# LPC43xx register map
File version: 5
Registers are 32-bit, read-write, reset 0x0 unless marked. A register's access mark holds for its fields unless they carry their own. Offsets are from the block's base; [hi:lo] are bit positions.

## ETHERNET (part 2 of 2) — Product name title=UM10430 Chapter title=LPC18xx Ethernet Modification date=12/9/2011 Major revision=1.1 Minor revision=not available
Base 0x40010000
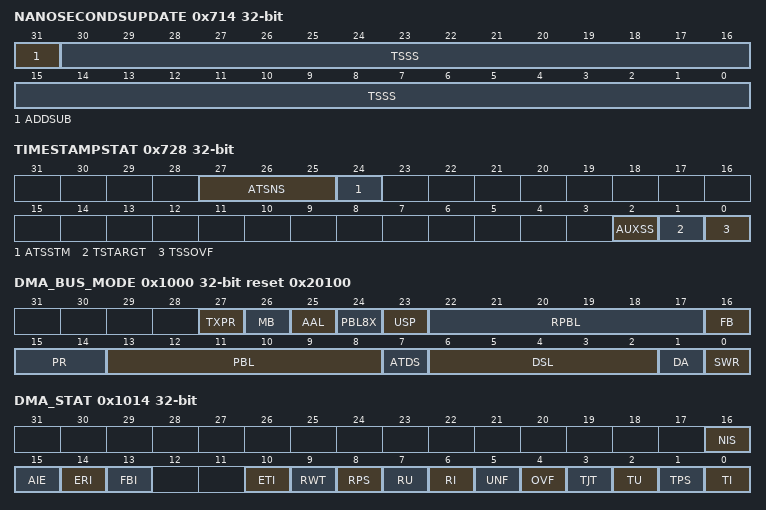
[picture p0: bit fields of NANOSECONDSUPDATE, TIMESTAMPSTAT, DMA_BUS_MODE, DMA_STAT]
0x714 NANOSECONDSUPDATE — System time nanoseconds update register
  [31] ADDSUB — Add or subtract time When this bit is set, the time value is subtracted with the contents of the update register. When this bit is reset, the time value is added with the contents of the update register.
  [30:0] TSSS — Time stamp sub seconds The value in this field has the sub second representation of time, with an accuracy of 0.46 nano-second. (When TSCTRLSSR is set in the time stamp control register, each bit represents 1 ns and the programmed value should not exceed 0x3B9A_C9FF.)
0x718 ADDEND — Time stamp addend register
  [31:0] TSAR — Time stamp addend This register indicates the 32-bit time value to be added to the Accumulator register to achieve time synchronization.
0x71C TARGETSECONDS — Target time seconds register
  [31:0] TSTR — Target time seconds register This register stores the time in seconds. When the time stamp value matches or exceeds both Target Time Stamp registers, the MAC, if enabled, generates an interrupt.
0x720 TARGETNANOSECONDS — Target time nanoseconds register
  [30:0] TSTR — Target time stamp low This register stores the time in (signed) nanoseconds. When the value of the Time Stamp matches the Target time stamp registers (both), the MAC will generate an interrupt if enabled. (This value should not exceed 0x3B9A_C9FF when TSCTRLSSR is set in the time stamp control register.)
0x724 HIGHWORD — System time higher word seconds register
  [15:0] TSHWR — Time stamp higher word Contains the most significant 16-bits of the time stamp seconds value. The register is directly written to initialize the value. This register is incremented when there is an overflow from the 32-bits of the System Time - Seconds register.
0x728 TIMESTAMPSTAT ro — Time stamp status register
  [27:25] ATSNS — Auxiliary Time Stamp Number of Snapshots These bits indicate the number of Snapshots available in the FIFO. A value of 4 (100) indicates that the Auxiliary Snapshot FIFO is full. These bits are cleared (to 000) when the Auxiliary snapshot FIFO clear bit is set.
  [24] ATSSTM — Auxiliary Time Stamp Snapshot Trigger Missed This bit is set when the Auxiliary time stamp snapshot FIFO is full and external trigger was set. This indicates that the latest snapshot was not stored in the FIFO.
  [2] AUXSS — Auxiliary Time Stamp Trigger Snapshot This bit is set high when the auxiliary snapshot is written to the FIFO.
  [1] TSTARGT — Time stamp target reached When set, indicates the value of system time is greater or equal to the value specified in the Target Time High and Low registers
  [0] TSSOVF — Time stamp seconds overflow When set, indicates that the seconds value of the time stamp (when supporting version 2 format) has overflowed beyond 0xFFFF_FFFF.
0x72C PPSCTRL — PPS control register
  [3:0] PPSCTRL — Control the duration between 2-pulses of PPS signal output This controls the duration between 2 pulses of the PPS output signal. By default the control is set to 1 second between pulses. The duration of the pulses for valid settings is mentioned below. 0000 = 1.0 sec (Binary and Digital Rollover) 0001 = 0.5 sec (Binary Rollover), 0.536 sec (Digital Rollover) 0010 = 0.25 sec (Binary Rollover), 0.26 sec (Digital Rollover) 0011 = 0.125 sec (Binary Rollover), 0.13 sec (Digital Rollover) ... 1111 = 15.28 msec (Binary Rollover), 32.77 microsec (Digital Rollover)
0x730 AUXNANOSECONDS ro — Auxiliary time stamp nanoseconds register
  [31:0] AUXNS — Lower 32 bits (nano-seconds field) of the auxiliary time stamp.
0x734 AUXSECONDS ro — Auxiliary time stamp seconds register
  [31:0] AUXS — Lower 32 bits of the Seconds field of the auxiliary time stamp .
0x1000 DMA_BUS_MODE reset 0x20100 — Bus Mode Register
  [27] TXPR — When set, this bit indicates that the transmit DMA has higher priority than the receive DMA during arbitration for the system-side bus.
  [26] MB — Mixed burst When this bit is set high and FB bit is low, the AHB master interface will start all bursts of length more than 16 with INCR (undefined burst) whereas it will revert to fixed burst transfers (INCRx and SINGLE) for burst-length of 16 and below.
  [25] AAL — Address-aligned beats When this bit is set high and the FB bit equals 1, the AHB interface generates all bursts aligned to the start address LS bits. If the FB bit equals 0, the first burst (accessing the data buffer's start address) is not aligned, but subsequent bursts are aligned to the address.
  [24] PBL8X — 8 x PBL mode When set high, this bit multiplies the PBL value programmed (bits [22:17] and bits [13:8]) eight times. Thus the DMA will transfer data in to a maximum of 8, 16, 32, 64, 128, and 256 beats depending on the PBL value. This bit function is not backward compatible. Before version 3.50a, this bit was 4xPBL.
  [23] USP — Use separate PBL When set high, it configures the RxDMA to use the value configured in bits [22:17] as PBL while the PBL value in bits [13:8] is applicable to TxDMA operations only. When reset to low, the PBL value in bits [13:8] is applicable for both DMA engines.
  [22:17] RPBL — RxDMA PBL These bits indicate the maximum number of beats to be transferred in one RxDMA transaction. This will be the maximum value that is used in a single block Read/Write. The RxDMA will always attempt to burst as specified in RPBL each time it starts a Burst transfer on the host bus. RPBL can be programmed with permissible values of 1, 2, 4, 8, 16, and 32. Any other value will result in undefined behavior. These bits are valid and applicable only when USP is set high.
  [16] FB — Fixed burst This bit controls whether the AHB Master interface performs fixed burst transfers or not. When set, the AHB will use only SINGLE, INCR4, INCR8 or INCR16 during start of normal burst transfers. When reset, the AHB will use SINGLE and INCR burst transfer operations.
  [15:14] PR — Rx-to-Tx priority ratio RxDMA requests given priority over TxDMA requests in the following ratio. This is valid only when the DA bit is reset. 00 = 1-to-1 01 = 2-to-1 10 = 3-to-1 11 = 4-to-1
  [13:8] PBL — Programmable burst length These bits indicate the maximum number of beats to be transferred in one DMA transaction. This will be the maximum value that is used in a single block Read/Write. The DMA will always attempt to burst as specified in PBL each time it starts a Burst transfer on the host bus. PBL can be programmed with permissible values of 1, 2, 4, 8, 16, and 32. Any other value will result in undefined behavior. When USP is set high, this PBL value is applicable for TxDMA transactions only. The PBL values have the following limitations. The maximum number of beats (PBL) possible is limited by the size of the Tx FIFO and Rx FIFO in the MTL layer and the data bus width on the DMA. The FIFO has a constraint that the maximum beat supported is half the depth of the FIFO, except when specified (as given below). For different data bus widths and FIFO sizes, the valid PBL range (including x8 mode) is provided in the following table. If the PBL is common for both transmit and receive DMA, the minimum Rx FIFO and Tx FIFO depths must be considered. Do not program out-of-range PBL values, because the system may not behave properly.
  [7] ATDS — Alternate descriptor size When set, the alternate descriptor (see Section 24.10.3) size is increased to 32 bytes (8 DWORDS). This is required when the Advanced Time-Stamp feature or Full IPC Offload Engine is enabled in the receiver. When reset, the descriptor size reverts back to 4 DWORDs (16 bytes).
  [6:2] DSL — Descriptor skip length This bit specifies the number of Word/Dword/Lword (depending on 32/64/128-bit bus) to skip between two unchained descriptors. The address skipping starts from the end of current descriptor to the start of next descriptor. When DSL value equals zero, then the descriptor table is taken as contiguous by the DMA, in Ring mode.
  [1] DA — DMA arbitration scheme 0 = Round-robin with Rx:Tx priority given in bits [15:14] 1 = Rx has priority over Tx
  [0] SWR — Software reset This register field can be read by the application (Read), can be set to 1 by the application with a register write of 1 (Write Set), and is cleared to 0 by the Ethernet core (Self Clear). The application cannot clear this type of field, and a register write of 0 to this bit has no effect on this field. When this bit is set, the MAC DMA Controller resets all MAC Subsystem internal registers and logic. It is cleared automatically after the reset operation has completed in all of the core clock domains. Read a 0 value in this bit before re-programming any register of the core. The reset operation is completed only when all the resets in all the active clock domains are de-asserted. Hence it is essential that all the PHY inputs clocks (applicable for the selected PHY interface) are present for software reset completion.
0x1004 DMA_TRANS_POLL_DEMAND — Transmit poll demand register
  [31:0] TPD — Transmit poll demand This register field can be read by the application, and when a write operation is performed with any data value, an event is triggered. When these bits are written with any value, the DMA reads the current descriptor pointed to by the Current Host Transmit Descriptor register (Section 24.6.40). If that descriptor is not available (owned by Host), transmission returns to the Suspend state and bit 2 in the DMA_STAT Register is asserted. If the descriptor is available, transmission resumes.
0x1008 DMA_REC_POLL_DEMAND — Receive poll demand register
  [31:0] RPD — Receive poll demand This register field can be read by the application, and when a write operation is performed with any data value, an event is triggered. When these bits are written with any value, the DMA reads the current descriptor pointed to by the Current Host Receive Descriptor register (Section 24.6.41). If that descriptor is not available (owned by Host), reception returns to the Suspended state and bit 7 in the DMA_STAT Register is not asserted. If the descriptor is available, the Receive DMA returns to active state.
0x100C DMA_REC_DES_ADDR — Receive descriptor list address register
  [31:0] SRL — Start of receive list This field contains the base address of the First Descriptor in the Receive Descriptor list. The LSB bits [1/2/3:0] for 32/64/128-bit bus width) will be ignored and taken as all-zero by the DMA internally. Hence these LSB bits are Read Only.
0x1010 DMA_TRANS_DES_ADDR — Transmit descriptor list address register
  [31:0] SRL — Start of transmit list This field contains the base address of the First Descriptor in the Transmit Descriptor list. The LSB bits [1/2/3:0] for 32/64/128-bit bus width) will be ignored and taken as all-zero by the DMA internally. Hence these LSB bits are Read Only.
0x1014 DMA_STAT — Status register
  [16] NIS — Normal interrupt summary Normal Interrupt Summary bit value is the logical OR of the following when the corresponding interrupt bits are enabled in the DMA_INT_EN register: DMA_STAT register, bit 0: Transmit interrupt DMA_STAT register, bit 2: Transmit buffer unavailable DMA_STAT register, bit 6: Receive interrupt DMA_STAT register, bit 14: Early receive interrupt Only unmasked bits affect the Normal Interrupt Summary bit. This is a sticky bit and must be cleared (by writing a 1 to this bit) each time a corresponding bit that causes NIS to be set is cleared.
  [15] AIE — Abnormal interrupt summary Abnormal Interrupt Summary bit value is the logical OR of the following when the corresponding interrupt bits are enabled in the DMA_INT_EN register: DMA_STAT register, bit 1: Transmit process stopped DMA_STAT register, bit 3: Transmit jabber timeout DMA_STAT register, bit 4: Receive overflow DMA_STAT register, bit 5: Transmit underflow DMA_STAT register, bit 7: Receiver buffer unavailable DMA_STAT register, bit 8: Receive process stopped DMA_STAT register, bit 9: Receive watchdog timeout DMA_STAT register, bit 10: Early transmit interrupt DMA_STAT register, bit 13: Fatal bus error Only unmasked bits affect the Abnormal Interrupt Summary bit. This is a sticky bit and must be cleared each time a corresponding bit that causes AIS to be set is cleared.
  [14] ERI — Early receive interrupt This bit indicates that the DMA had filled the first data buffer of the packet. Receive Interrupt bit 6 in this register automatically clears this bit.
  [13] FBI — Fatal bus error interrupt This bit indicates that a bus error occurred, as detailed in bits [25:23]. When this bit is set, the corresponding DMA engine disables all its bus accesses.
  [10] ETI — Early transmit interrupt This bit indicates that the frame to be transmitted was fully transferred to the MTL Transmit FIFO.
  [9] RWT — Receive watchdog timeout This bit is asserted when a frame with a length greater than 2,048 bytes is received (10,240 when Jumbo Frame mode is enabled).
  [8] RPS — Received process stopped This bit is asserted when the Receive Process enters the Stopped state.
  [7] RU — Receive buffer unavailable This bit indicates that the Next Descriptor in the Receive List is owned by the host and cannot be acquired by the DMA. Receive Process is suspended. To resume processing Receive descriptors, the host should change the ownership of the descriptor and issue a Receive Poll Demand command. If no Receive Poll Demand is issued, Receive Process resumes when the next recognized incoming frame is received. This bit is set only when the previous Receive Descriptor was owned by the DMA.
  [6] RI — Receive interrupt This bit indicates the completion of frame reception. Specific frame status information has been posted in the descriptor. Reception remains in the Running state.
  [5] UNF — Transmit underflow This bit indicates that the Transmit Buffer had an Underflow during frame transmission. Transmission is suspended and an Underflow Error TDES0[1] is set.
  [4] OVF — Receive overflow This bit indicates that the Receive Buffer had an Overflow during frame reception. If the partial frame is transferred to application, the overflow status is set in RDES0[11].
  [3] TJT — Transmit jabber timeout This bit indicates that the Transmit Jabber Timer expired, meaning that the transmitter had been excessively active. The transmission process is aborted and placed in the Stopped state. This causes the Transmit Jabber Timeout TDES0[14] flag to assert.
  [2] TU — Transmit buffer unavailable This bit indicates that the Next Descriptor in the Transmit List is owned by the host and cannot be acquired by the DMA. Transmission is suspended. Bits[22:20] explain the Transmit Process state transitions. To resume processing transmit descriptors, the host should change the ownership of the bit of the descriptor and then issue a Transmit Poll Demand command.
  [1] TPS — Transmit process stopped This bit is set when the transmission is stopped.
  [0] TI — Transmit interrupt This bit indicates that frame transmission is finished and TDES1[31] is set in the First Descriptor.
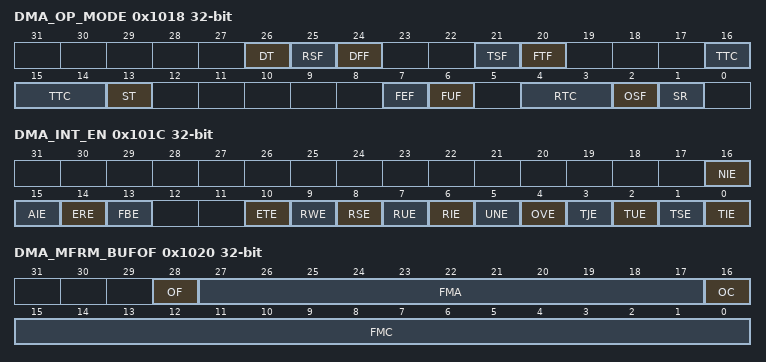
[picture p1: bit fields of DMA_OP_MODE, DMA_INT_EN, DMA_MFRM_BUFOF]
0x1018 DMA_OP_MODE — Operation mode register
  [26] DT — Disable Dropping of TCP/IP Checksum Error Frames When this bit is set, the core does not drop frames that only have errors detected by the Receive Checksum Offload engine. Such frames do not have any errors (including FCS error) in the Ethernet frame received by the MAC but have errors in the encapsulated payload only. When this bit is reset, all error frames are dropped if the FEF bit is reset.
  [25] RSF — Receive store and forward When this bit is set, the MTL only reads a frame from the Rx FIFO after the complete frame has been written to it, ignoring RTC bits. When this bit is reset, the Rx FIFO operates in Cut-Through mode, subject to the threshold specified by the RTC bits.
  [24] DFF — Disable flushing of received frames When this bit is set, the RxDMA does not flush any frames due to the unavailability of receive descriptors/buffers as it does normally when this bit is reset. (See).
  [21] TSF — Transmit store and forward When this bit is set, transmission starts when a full frame resides in the MTL Transmit FIFO. When this bit is set, the TTC values specified in this register (bits [16:14]) are ignored. This bit should be changed only when transmission is stopped.
  [20] FTF — Flush transmit FIFO This register field can be read by the application (Read), can be set to 1 by the application with a register write of 1 (Write Set), and is cleared to 0 by the Ethernet core (Self Clear). The application cannot clear this type of field, and a register write of 0 to this bit has no effect on this field. When this bit is set, the transmit FIFO controller logic is reset to its default values and thus all data in the Tx FIFO is lost/flushed. This bit is cleared internally when the flushing operation is completed fully. The Operation Mode register should not be written to until this bit is cleared. The data which is already accepted by the MAC transmitter will not be flushed. It will be scheduled for transmission and will result in underflow and runt frame transmission. The flush operation completes only after emptying the TxFIFO of its contents and all the pending Transmit Status of the transmitted frames are accepted by the host. In order to complete this flush operation, the PHY transmit clock is required to be active.
  [16:14] TTC — Transmit threshold control These three bits control the threshold level of the MTL Transmit FIFO. Transmission starts when the frame size within the MTL Transmit FIFO is larger than the threshold. In addition, full frames with a length less than the threshold are also transmitted. These bits are used only when the TSF bit (Bit 21) is reset. 000 = 64 001 = 128 010 = 192 011 = 256 100 = 40 101 = 32 110 = 24 111 = 16
  [13] ST — Start/Stop Transmission Command When this bit is set, transmission is placed in the Running state, and the DMA checks the Transmit List at the current position for a frame to be transmitted. Descriptor acquisition is attempted either from the current position in the list, which is the Transmit List Base Address set by the DMA_TRANS_DES_ADDR register or from the position retained when transmission was stopped previously. If the current descriptor is not owned by the DMA, transmission enters the Suspended state and Transmit Buffer Unavailable (DMA_STAT register, bit 2) is set. The Start Transmission command is effective only when transmission is stopped. If the command is issued before setting the DMA_TRANS_DES_ADDR register, then the DMA behavior is unpredictable. When this bit is reset, the transmission process is placed in the Stopped state after completing the transmission of the current frame. The Next Descriptor position in the Transmit List is saved, and becomes the current position when transmission is restarted. The stop transmission command is effective only the transmission of the current frame is complete or when the transmission is in the Suspended state.
  [7] FEF — Forward error frames When this bit is reset, the Rx FIFO drops frames with error status (CRC error, collision error, GMII_ER, giant frame, watchdog timeout, overflow). However, if the frame's start byte (write) pointer is already transferred to the read controller side (in Threshold mode), then the frames are not dropped. When FEF is set, all frames except runt error frames are forwarded to the DMA. But when RxFIFO overflows when a partial frame is written, then such frames are dropped even when FEF is set.
  [6] FUF — Forward undersized good frames When set, the Rx FIFO will forward Undersized frames (frames with no Error and length less than 64 bytes) including pad-bytes and CRC). When reset, the Rx FIFO will drop all frames of less than 64 bytes, unless it is already transferred due to lower value of Receive Threshold (e.g., RTC = 01).
  [4:3] RTC — Receive threshold control These two bits control the threshold level of the MTL Receive FIFO. Transfer (request) to DMA starts when the frame size within the MTL Receive FIFO is larger than the threshold. In addition, full frames with a length less than the threshold are transferred automatically. Note that value of 11 is not applicable if the configured Receive FIFO size is 128 bytes. These bits are valid only when the RSF bit is zero, and are ignored when the RSF bit is set to 1. 00 = 64 01 = 32 10 = 96 11 = 128
  [2] OSF — Operate on second frame When this bit is set, this bit instructs the DMA to process a second frame of Transmit data even before status for first frame is obtained.
  [1] SR — Start/stop receive When this bit is set, the Receive process is placed in the Running state. The DMA attempts to acquire the descriptor from the Receive list and processes incoming frames. Descriptor acquisition is attempted from the current position in the list, which is the address set by the DMA_REC_DES_ADDR register or the position retained when the Receive process was previously stopped. If no descriptor is owned by the DMA, reception is suspended and Receive Buffer Unavailable bit (bit 7 in DMA_STAT register) is set. The Start Receive command is effective only when reception has stopped. If the command was issued before setting the DMA_REC_DES_ADDR, DMA behavior is unpredictable.
0x101C DMA_INT_EN — Interrupt enable register
  [16] NIE — Normal interrupt summary enable When this bit is set, a normal interrupt is enabled. When this bit is reset, a normal interrupt is disabled. This bit enables the following bits: DMA_STAT register, bit 0: Transmit interrupt DMA_STAT register, bit 2: Transmit buffer unavailable DMA_STAT register, bit 6: Receive interrupt DMA_STAT register, bit 14: Early receive interrupt
  [15] AIE — Abnormal interrupt summary enable When this bit is set, an Abnormal Interrupt is enabled. When this bit is reset, an Abnormal Interrupt is disabled. This bit enables the following bits DMA_STAT register, bit 1: Transmit process stopped DMA_STAT register, bit 3: Transmit jabber timeout DMA_STAT register, bit 4: Receive overflow DMA_STAT register, bit 5: Transmit underflow DMA_STAT register, bit 7: Receiver buffer unavailable DMA_STAT register, bit 8: Receive process stopped DMA_STAT register, bit 9: Receive watchdog timeout DMA_STAT register, bit 10: Early transmit interrupt DMA_STAT register, bit 13: Fatal bus error
  [14] ERE — Early receive interrupt enable When this bit is set with Normal Interrupt Summary Enable (bit 16 in this register), Early Receive Interrupt is enabled. When this bit is reset, Early Receive Interrupt is disabled.
  [13] FBE — Fatal bus error enable When this bit is set with Abnormal Interrupt Summary Enable (bit 15 in this register), the Fatal Bus Error Interrupt is enabled. When this bit is reset, Fatal Bus Error Enable Interrupt is disabled.
  [10] ETE — Early transmit interrupt enable When this bit is set with an Abnormal Interrupt Summary Enable (bit 15 in this register), Early Transmit Interrupt is enabled. When this bit is reset, Early Transmit Interrupt is disabled.
  [9] RWE — Receive watchdog timeout enable When this bit is set with Abnormal Interrupt Summary Enable (bit 15 in this register), the Receive Watchdog Timeout Interrupt is enabled. When this bit is reset, Receive Watchdog Timeout Interrupt is disabled.
  [8] RSE — Received stopped enable When this bit is set with Abnormal Interrupt Summary Enable (bit 15 in this register), Receive Stopped Interrupt is enabled. When this bit is reset, Receive Stopped Interrupt is disabled.
  [7] RUE — Receive buffer unavailable enable When this bit is set with Abnormal Interrupt Summary Enable (bit 15 in this register), Receive Buffer Unavailable Interrupt is enabled. When this bit is reset, the Receive Buffer Unavailable Interrupt is disabled.
  [6] RIE — Receive interrupt enable When this bit is set with Normal Interrupt Summary Enable (bit 16 in this register), Receive Interrupt is enabled. When this bit is reset, Receive Interrupt is disabled.
  [5] UNE — Underflow interrupt enable When this bit is set with Abnormal Interrupt Summary Enable (bit 15 in this register), Transmit Underflow Interrupt is enabled. When this bit is reset, Underflow Interrupt is disabled.
  [4] OVE — Overflow interrupt enable When this bit is set with Abnormal Interrupt Summary Enable (bit 15 in this register), Receive Overflow Interrupt is enabled. When this bit is reset, Overflow Interrupt is disabled.
  [3] TJE — Transmit jabber timeout enable When this bit is set with Abnormal Interrupt Summary Enable (bit 15 in this register), Transmit Jabber Timeout Interrupt is enabled. When this bit is reset, Transmit Jabber Timeout Interrupt is disabled.
  [2] TUE — Transmit buffer unavailable enable When this bit is set with Normal Interrupt Summary Enable (bit 16 in this register), Transmit Buffer Unavailable Interrupt is enabled. When this bit is reset, Transmit Buffer Unavailable Interrupt is disabled.
  [1] TSE — Transmit stopped enable When this bit is set with Abnormal Interrupt Summary Enable (bit 15 in this register), Transmission Stopped Interrupt is enabled. When this bit is reset, Transmission Stopped Interrupt is disabled.
  [0] TIE — Transmit interrupt enable When this bit is set with Normal Interrupt Summary Enable (bit 16 in this register), Transmit Interrupt is enabled. When this bit is reset, Transmit Interrupt is disabled.
0x1020 DMA_MFRM_BUFOF ro — Missed frame and buffer overflow register
  [28] OF — Overflow bit for FIFO overflow counter This register field can be read by the application (Read), can be set to 1 by the Ethernet core on a certain internal event (Self Set), and is automatically cleared to 0 on a register read. A register write of 0 has no effect on this field.
  [27:17] FMA — Number of frames missed by the application This register field can be read by the application (Read), can be set to 1 by the Ethernet core on a certain internal event (Self Set), and is automatically cleared to 0 on a register read. A register write of 0 has no effect on this field. Indicates the number of frames missed by the application. This counter is incremented each time the MTL asserts the sideband signal mtl_rxoverflow_o. The counter is cleared when this register is read with .
  [16] OC — Overflow bit for missed frame counter This register field can be read by the application (Read), can be set to 1 by the Ethernet core on a certain internal event (Self Set), and is automatically cleared to 0 on a register read. A register write of 0 has no effect on this field.
  [15:0] FMC — Number of frames missed This register field can be read by the application (Read), can be set to 1 by the Ethernet core on a certain internal event (Self Set), and is automatically cleared to 0 on a register read. A register write of 0 has no effect on this field. Indicates the number of frames missed by the controller due to the Host Receive Buffer being unavailable. This counter is incremented each time the DMA discards an incoming frame. The counter is cleared when this register is read with.
0x1024 DMA_REC_INT_WDT — Receive interrupt watchdog timer register
  [7:0] RIWT — RI watchdog timeout Indicates the number of system clock cycles multiplied by 256 for which the watchdog timer is set. The watchdog timer gets triggered with the programmed value after the RxDMA completes the transfer of a frame for which the RI status bit is not set due to the setting in the corresponding descriptor RDES1[31]. When the watch-dog timer runs out, the RI bit is set and the timer is stopped. The watchdog timer is reset when RI bit is set high due to automatic setting of RI as per RDES1[31] of any received frame.
0x1048 DMA_CURHOST_TRANS_DES ro — Current host transmit descriptor register
  [31:0] HTD — Host Transmit Descriptor Address Pointer Cleared on Reset. Pointer updated by DMA during operation.
0x104C DMA_CURHOST_REC_DES ro — Current host receive descriptor register
  [31:0] HRD — Host Receive Descriptor Address Pointer Cleared on Reset. Pointer updated by DMA during operation.
0x1050 DMA_CURHOST_TRANS_BUF ro — Current host transmit buffer address register
  [31:0] HTB — Host Transmit Buffer Address Pointer Cleared on Reset. Pointer updated by DMA during operation.
0x1054 DMA_CURHOST_REC_BUF ro — Current host receive buffer address register
  [31:0] HRB — Host Receive Buffer Address Pointer Cleared on Reset. Pointer updated by DMA during operation.
